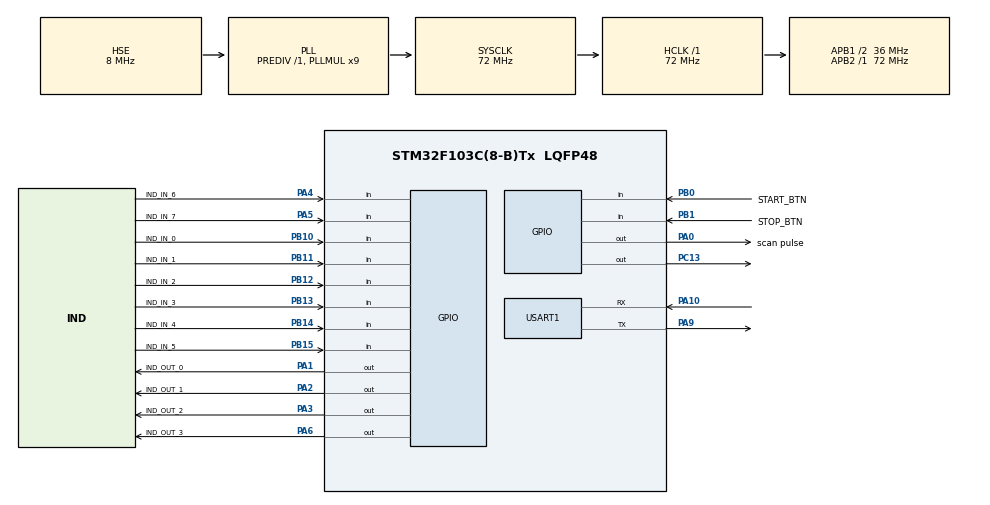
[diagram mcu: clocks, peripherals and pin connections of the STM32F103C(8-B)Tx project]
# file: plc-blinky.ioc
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Mcu.Family=STM32F1
Mcu.Name=STM32F103C(8-B)Tx
Mcu.Package=LQFP48
NVIC.PriorityGroup=NVIC_PRIORITYGROUP_4
NVIC.TIM2_IRQn=true\:0\:0\:false\:false\:true\:true\:true\:true
NVIC.USART1_IRQn=true\:0\:0\:false\:false\:true\:true\:true\:true
PA0-WKUP.GPIO_Label=scan pulse
PA0-WKUP.Signal=GPIO_Output
PA1.GPIO_Label=IND_OUT_0
PA1.Signal=GPIO_Output
PA10.Mode=Asynchronous
PA10.Signal=USART1_RX
PA13.Mode=Serial_Wire
PA13.Signal=SYS_JTMS-SWDIO
PA14.Mode=Serial_Wire
PA14.Signal=SYS_JTCK-SWCLK
PA2.GPIO_Label=IND_OUT_1
PA2.Signal=GPIO_Output
PA3.GPIO_Label=IND_OUT_2
PA3.Signal=GPIO_Output
PA4.GPIO_Label=IND_IN_6
PA4.GPIO_PuPd=GPIO_PULLUP
PA4.Signal=GPIO_Input
PA5.GPIO_Label=IND_IN_7
PA5.GPIO_PuPd=GPIO_PULLUP
PA5.Signal=GPIO_Input
PA6.GPIO_Label=IND_OUT_3
PA6.Signal=GPIO_Output
PA9.Mode=Asynchronous
PA9.Signal=USART1_TX
PB0.GPIO_Label=START_BTN
PB0.GPIO_PuPd=GPIO_PULLUP
PB0.Signal=GPIO_Input
PB1.GPIO_Label=STOP_BTN
PB1.GPIO_PuPd=GPIO_PULLUP
PB1.Signal=GPIO_Input
PB10.GPIO_Label=IND_IN_0
PB10.GPIO_PuPd=GPIO_PULLUP
PB10.Signal=GPIO_Input
PB11.GPIO_Label=IND_IN_1
PB11.GPIO_PuPd=GPIO_PULLUP
PB11.Signal=GPIO_Input
PB12.GPIO_Label=IND_IN_2
PB12.GPIO_PuPd=GPIO_PULLUP
PB12.Signal=GPIO_Input
PB13.GPIO_Label=IND_IN_3
PB13.GPIO_PuPd=GPIO_PULLUP
PB13.Signal=GPIO_Input
PB14.GPIO_Label=IND_IN_4
PB14.GPIO_PuPd=GPIO_PULLUP
PB14.Signal=GPIO_Input
PB15.GPIO_Label=IND_IN_5
PB15.GPIO_PuPd=GPIO_PULLUP
PB15.Signal=GPIO_Input
PC13-TAMPER-RTC.Signal=GPIO_Output
PD0-OSC_IN.Mode=HSE-External-Oscillator
PD0-OSC_IN.Signal=RCC_OSC_IN
PD1-OSC_OUT.Mode=HSE-External-Oscillator
PD1-OSC_OUT.Signal=RCC_OSC_OUT
ProjectManager.HeapSize=0x200
ProjectManager.StackSize=0x400
ProjectManager.TargetToolchain=STM32CubeIDE
RCC.AHBFreq_Value=72000000
RCC.APB1CLKDivider=RCC_HCLK_DIV2
RCC.APB1Freq_Value=36000000
RCC.APB1TimFreq_Value=72000000
RCC.APB2Freq_Value=72000000
RCC.APB2TimFreq_Value=72000000
RCC.HCLKFreq_Value=72000000
RCC.PLLMUL=RCC_PLL_MUL9
RCC.PLLSourceVirtual=RCC_PLLSOURCE_HSE
RCC.SYSCLKFreq_VALUE=72000000
RCC.SYSCLKSource=RCC_SYSCLKSOURCE_PLLCLK
RCC.USBFreq_Value=72000000
TIM2.Period=100 - 1
TIM2.Prescaler=7200 - 1
USART1.VirtualMode=VM_ASYNC
VP_TIM2_VS_ClockSourceINT.Mode=Internal
board=custom

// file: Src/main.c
/* USER CODE BEGIN Header */
/**
  ******************************************************************************
  * @file           : main.c
  * @brief          : Main program body
  ******************************************************************************
  * @attention
  *
  * Copyright (c) 2026 STMicroelectronics.
  * All rights reserved.
  *
  * This software is licensed under terms that can be found in the LICENSE file
  * in the root directory of this software component.
  * If no LICENSE file comes with this software, it is provided AS-IS.
  *
  ******************************************************************************
  */
/* USER CODE END Header */
#include "main.h"

/* USER CODE BEGIN Includes */
#include "scan_engine.h"
#include "uart_console.h"
/* USER CODE END Includes */

TIM_HandleTypeDef htim2;

UART_HandleTypeDef huart1;

void SystemClock_Config(void);
static void MX_GPIO_Init(void);
static void MX_TIM2_Init(void);
static void MX_USART1_UART_Init(void);

int main(void)
{

  /* MCU Configuration--------------------------------------------------------*/

  /* Reset of all peripherals, Initializes the Flash interface and the Systick. */
  HAL_Init();

  /* Configure the system clock */
  SystemClock_Config();

  /* Initialize all configured peripherals */
  MX_GPIO_Init();
  MX_TIM2_Init();
  MX_USART1_UART_Init();
  /* USER CODE BEGIN 2 */
  scan_engine_init();
  HAL_TIM_Base_Start_IT(&htim2);
  uart_console_init();
  /* USER CODE END 2 */

  /* Infinite loop */
  while (1)
  {

    /* USER CODE BEGIN 3 */
	  uart_console_poll();
  }
  /* USER CODE END 3 */
}

void SystemClock_Config(void)
{
  RCC_OscInitTypeDef RCC_OscInitStruct = {0};
  RCC_ClkInitTypeDef RCC_ClkInitStruct = {0};

  /** Initializes the RCC Oscillators according to the specified parameters
  * in the RCC_OscInitTypeDef structure.
  */
  RCC_OscInitStruct.OscillatorType = RCC_OSCILLATORTYPE_HSE;
  RCC_OscInitStruct.HSEState = RCC_HSE_ON;
  RCC_OscInitStruct.HSEPredivValue = RCC_HSE_PREDIV_DIV1;
  RCC_OscInitStruct.HSIState = RCC_HSI_ON;
  RCC_OscInitStruct.PLL.PLLState = RCC_PLL_ON;
  RCC_OscInitStruct.PLL.PLLSource = RCC_PLLSOURCE_HSE;
  RCC_OscInitStruct.PLL.PLLMUL = RCC_PLL_MUL9;
  if (HAL_RCC_OscConfig(&RCC_OscInitStruct) != HAL_OK)
  {
    Error_Handler();
  }

  /** Initializes the CPU, AHB and APB buses clocks
  */
  RCC_ClkInitStruct.ClockType = RCC_CLOCKTYPE_HCLK|RCC_CLOCKTYPE_SYSCLK
                              |RCC_CLOCKTYPE_PCLK1|RCC_CLOCKTYPE_PCLK2;
  RCC_ClkInitStruct.SYSCLKSource = RCC_SYSCLKSOURCE_PLLCLK;
  RCC_ClkInitStruct.AHBCLKDivider = RCC_SYSCLK_DIV1;
  RCC_ClkInitStruct.APB1CLKDivider = RCC_HCLK_DIV2;
  RCC_ClkInitStruct.APB2CLKDivider = RCC_HCLK_DIV1;

  if (HAL_RCC_ClockConfig(&RCC_ClkInitStruct, FLASH_LATENCY_2) != HAL_OK)
  {
    Error_Handler();
  }
}

static void MX_TIM2_Init(void)
{

  TIM_ClockConfigTypeDef sClockSourceConfig = {0};
  TIM_MasterConfigTypeDef sMasterConfig = {0};

  htim2.Instance = TIM2;
  htim2.Init.Prescaler = 7200 - 1;
  htim2.Init.CounterMode = TIM_COUNTERMODE_UP;
  htim2.Init.Period = 100 - 1;
  htim2.Init.ClockDivision = TIM_CLOCKDIVISION_DIV1;
  htim2.Init.AutoReloadPreload = TIM_AUTORELOAD_PRELOAD_DISABLE;
  if (HAL_TIM_Base_Init(&htim2) != HAL_OK)
  {
    Error_Handler();
  }
  sClockSourceConfig.ClockSource = TIM_CLOCKSOURCE_INTERNAL;
  if (HAL_TIM_ConfigClockSource(&htim2, &sClockSourceConfig) != HAL_OK)
  {
    Error_Handler();
  }
  sMasterConfig.MasterOutputTrigger = TIM_TRGO_RESET;
  sMasterConfig.MasterSlaveMode = TIM_MASTERSLAVEMODE_DISABLE;
  if (HAL_TIMEx_MasterConfigSynchronization(&htim2, &sMasterConfig) != HAL_OK)
  {
    Error_Handler();
  }

}

static void MX_USART1_UART_Init(void)
{

  huart1.Instance = USART1;
  huart1.Init.BaudRate = 115200;
  huart1.Init.WordLength = UART_WORDLENGTH_8B;
  huart1.Init.StopBits = UART_STOPBITS_1;
  huart1.Init.Parity = UART_PARITY_NONE;
  huart1.Init.Mode = UART_MODE_TX_RX;
  huart1.Init.HwFlowCtl = UART_HWCONTROL_NONE;
  huart1.Init.OverSampling = UART_OVERSAMPLING_16;
  if (HAL_UART_Init(&huart1) != HAL_OK)
  {
    Error_Handler();
  }

}

static void MX_GPIO_Init(void)
{
  GPIO_InitTypeDef GPIO_InitStruct = {0};

  /* GPIO Ports Clock Enable */
  __HAL_RCC_GPIOC_CLK_ENABLE();
  __HAL_RCC_GPIOD_CLK_ENABLE();
  __HAL_RCC_GPIOA_CLK_ENABLE();
  __HAL_RCC_GPIOB_CLK_ENABLE();

  /*Configure GPIO pin Output Level */
  HAL_GPIO_WritePin(GPIOC, GPIO_PIN_13, GPIO_PIN_RESET);

  /*Configure GPIO pin Output Level */
  HAL_GPIO_WritePin(GPIOA, scan_pulse_Pin|IND_OUT_0_Pin|IND_OUT_1_Pin|IND_OUT_2_Pin
                          |IND_OUT_3_Pin, GPIO_PIN_RESET);

  /*Configure GPIO pin : PC13 */
  GPIO_InitStruct.Pin = GPIO_PIN_13;
  GPIO_InitStruct.Mode = GPIO_MODE_OUTPUT_PP;
  GPIO_InitStruct.Pull = GPIO_NOPULL;
  GPIO_InitStruct.Speed = GPIO_SPEED_FREQ_LOW;
  HAL_GPIO_Init(GPIOC, &GPIO_InitStruct);

  /*Configure GPIO pins : scan_pulse_Pin IND_OUT_0_Pin IND_OUT_1_Pin IND_OUT_2_Pin
                           IND_OUT_3_Pin */
  GPIO_InitStruct.Pin = scan_pulse_Pin|IND_OUT_0_Pin|IND_OUT_1_Pin|IND_OUT_2_Pin
                          |IND_OUT_3_Pin;
  GPIO_InitStruct.Mode = GPIO_MODE_OUTPUT_PP;
  GPIO_InitStruct.Pull = GPIO_NOPULL;
  GPIO_InitStruct.Speed = GPIO_SPEED_FREQ_LOW;
  HAL_GPIO_Init(GPIOA, &GPIO_InitStruct);

  /*Configure GPIO pins : IND_IN_6_Pin IND_IN_7_Pin */
  GPIO_InitStruct.Pin = IND_IN_6_Pin|IND_IN_7_Pin;
  GPIO_InitStruct.Mode = GPIO_MODE_INPUT;
  GPIO_InitStruct.Pull = GPIO_PULLUP;
  HAL_GPIO_Init(GPIOA, &GPIO_InitStruct);

  /*Configure GPIO pins : START_BTN_Pin STOP_BTN_Pin IND_IN_0_Pin IND_IN_1_Pin
                           IND_IN_2_Pin IND_IN_3_Pin IND_IN_4_Pin IND_IN_5_Pin */
  GPIO_InitStruct.Pin = START_BTN_Pin|STOP_BTN_Pin|IND_IN_0_Pin|IND_IN_1_Pin
                          |IND_IN_2_Pin|IND_IN_3_Pin|IND_IN_4_Pin|IND_IN_5_Pin;
  GPIO_InitStruct.Mode = GPIO_MODE_INPUT;
  GPIO_InitStruct.Pull = GPIO_PULLUP;
  HAL_GPIO_Init(GPIOB, &GPIO_InitStruct);

}

/* USER CODE BEGIN 4 */
void HAL_TIM_PeriodElapsedCallback(TIM_HandleTypeDef *htim) {
    if (htim->Instance == TIM2) {
        scan_cycle_run();
    }
}
void HAL_UART_RxCpltCallback(UART_HandleTypeDef *huart) {
    if (huart->Instance == USART1) {
        void uart_console_on_rx(void);
        uart_console_on_rx();
    }
}
/* USER CODE END 4 */

void Error_Handler(void)
{
  __disable_irq();
  while (1)
  {
  }
}
